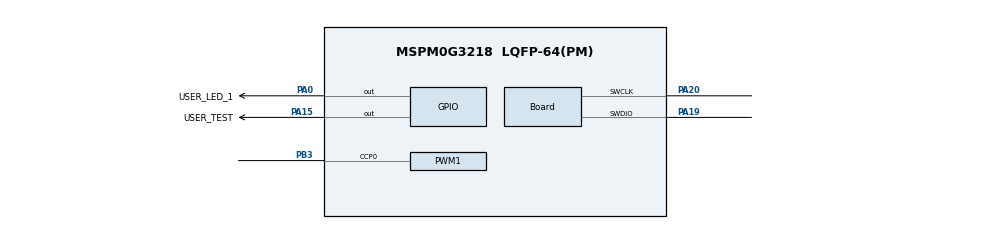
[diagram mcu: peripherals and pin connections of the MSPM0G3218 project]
//@cliArgs --device "MSPM0G321X" --package "LQFP-64(PM)" --part "Default"
//@v2CliArgs --device "MSPM0G3218" --package "LQFP-64(PM)"
// @cliArgs --board /ti/boards/LP_MSPM0G3218 --rtos nortos

/**
 * Import the modules used in this configuration.
 */
const GPIO   = scripting.addModule("/ti/driverlib/GPIO", {}, false);
const GPIO1  = GPIO.addInstance();
const PWM    = scripting.addModule("/ti/driverlib/PWM", {}, false);
const PWM1   = PWM.addInstance();
const SYSCTL = scripting.addModule("/ti/driverlib/SYSCTL");

/**
 * Write custom configuration values to the imported modules.
 */
const gate7  = system.clockTree["MFCLKGATE"];
gate7.enable = true;

GPIO1.$name                                 = "GPIO_LEDS";
GPIO1.associatedPins.create(2);
GPIO1.associatedPins[0].$name               = "USER_LED_1";
GPIO1.associatedPins[0].assignedPort        = "PORTA";
GPIO1.associatedPins[0].assignedPin         = "0";
GPIO1.associatedPins[0].initialValue        = "SET";
GPIO1.associatedPins[0].pin.$assign         = "PA0";
GPIO1.associatedPins[1].assignedPort        = "PORTA";
GPIO1.associatedPins[1].assignedPortSegment = "Lower";
GPIO1.associatedPins[1].$name               = "USER_TEST";
GPIO1.associatedPins[1].initialValue        = "SET";
GPIO1.associatedPins[1].pin.$assign         = "PA15";

const Board                       = scripting.addModule("/ti/driverlib/Board", {}, false);
Board.peripheral.$assign          = "DEBUGSS";
Board.peripheral.swclkPin.$assign = "PA20";
Board.peripheral.swdioPin.$assign = "PA19";

PWM1.$name                          = "PWM_0";
PWM1.dbRiseDelayTimerCount          = 50;
PWM1.dbFallDelayTimerCount          = 25;
PWM1.ccIndex                        = [0];
PWM1.clockSource                    = "MFCLK";
PWM1.clockPrescale                  = 4;
PWM1.timerCount                     = 8191;
PWM1.enableShadowLoad               = true;
PWM1.interrupts                     = ["CC0_DN_EVENT"];
PWM1.peripheral.$assign             = "TIMA0";
PWM1.peripheral.ccp0Pin.$assign     = "PB3";
PWM1.PWM_CHANNEL_0.$name            = "ti_driverlib_pwm_PWMTimerCC0";
PWM1.PWM_CHANNEL_0.ccValue          = 799;
PWM1.PWM_CHANNEL_0.shadowUpdateMode = "ZERO_EVT";

SYSCTL.MFCLKEn               = true;
SYSCTL.forceDefaultClkConfig = true;
SYSCTL.clockTreeEn           = true;

const ProjectConfig              = scripting.addModule("/ti/project_config/ProjectConfig", {}, false);
ProjectConfig.migrationCondition = true;
